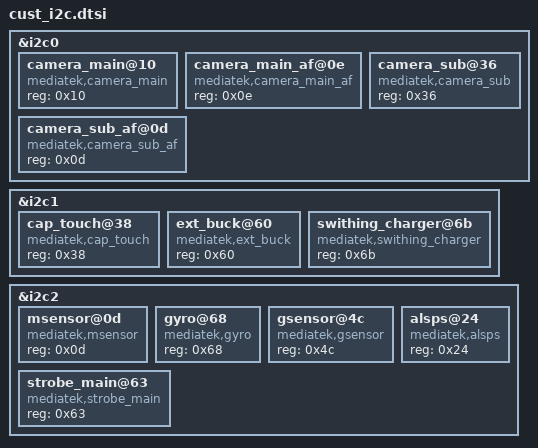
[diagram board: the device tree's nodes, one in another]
/*
 * Generated by MTK SP Drv_CodeGen Version 03.13.6  for MT6735. Copyright MediaTek Inc. (C) 2013.
 * Thu Jun  4 21:49:55 2015
 * Do Not Modify the File.
 */

/*************************
 * I2C dtsi file
*************************/

&i2c0 {
	camera_main@10 {
		compatible = "mediatek,camera_main";
		reg = <0x10>;
	};

	camera_main_af@0e {
		compatible = "mediatek,camera_main_af";
		reg = <0x0e>;
	};

	camera_sub@36 {
		compatible = "mediatek,camera_sub";
		reg = <0x36>;
	};

	camera_sub_af@0d {
		compatible = "mediatek,camera_sub_af";
		reg = <0x0d>;
	};
};

&i2c1 {
	cap_touch@38 {
		compatible = "mediatek,cap_touch";
		reg = <0x38>;
	};

	ext_buck@60 {
		compatible = "mediatek,ext_buck";
		reg = <0x60>;
	};

	swithing_charger@6b {
		compatible = "mediatek,swithing_charger";
		reg = <0x6b>;
	};

};

&i2c2 {
	msensor@0d {
		compatible = "mediatek,msensor";
		reg = <0x0d>;
	};

	gyro@68 {
		compatible = "mediatek,gyro";
		reg = <0x68>;
	};

	gsensor@4c {
		compatible = "mediatek,gsensor";
		reg = <0x4c>;
	};

	alsps@24 {
		compatible = "mediatek,alsps";
		reg = <0x24>;
	};

	strobe_main@63 {
		compatible = "mediatek,strobe_main";
		reg = <0x63>;
	};

};

